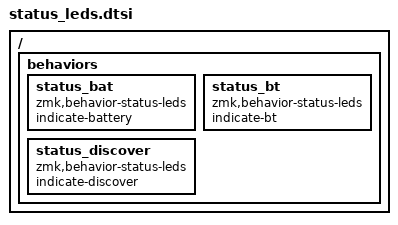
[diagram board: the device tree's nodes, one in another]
/ {
    behaviors {
        /omit-if-no-ref/ status_bat: status_bat {
            compatible = "zmk,behavior-status-leds";
            #binding-cells = <0>;
            indicate-battery;
        };

        /omit-if-no-ref/ status_bt: status_bt {
            compatible = "zmk,behavior-status-leds";
            #binding-cells = <0>;
            indicate-bt;
        };

        /omit-if-no-ref/ status_discover: status_discover {
            compatible = "zmk,behavior-status-leds";
            #binding-cells = <0>;
            indicate-discover;
        };
    };
};
